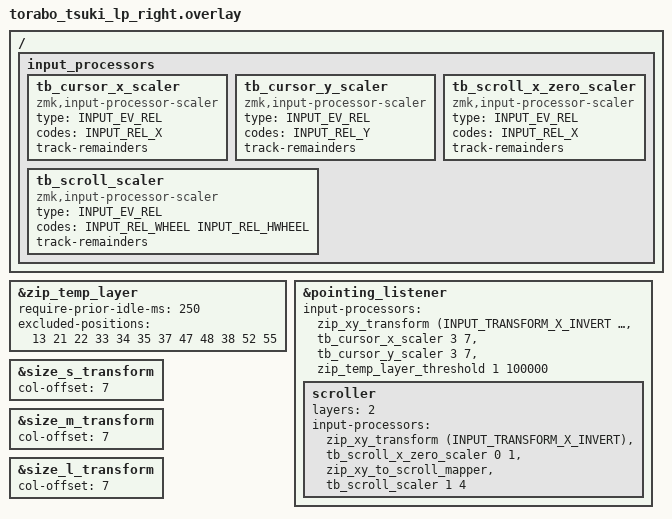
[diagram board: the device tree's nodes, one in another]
#include "torabo_tsuki_lp.dtsi"
#include <input/processors.dtsi>
#include <dt-bindings/zmk/input_transform.h>
#include <zephyr/dt-bindings/input/input-event-codes.h>

/ {
    input_processors {
        tb_cursor_x_scaler: tb_cursor_x_scaler {
            compatible = "zmk,input-processor-scaler";
            #input-processor-cells = <2>;
            type = <INPUT_EV_REL>;
            codes = <INPUT_REL_X>;
            track-remainders;
        };

        tb_cursor_y_scaler: tb_cursor_y_scaler {
            compatible = "zmk,input-processor-scaler";
            #input-processor-cells = <2>;
            type = <INPUT_EV_REL>;
            codes = <INPUT_REL_Y>;
            track-remainders;
        };

        tb_scroll_scaler: tb_scroll_scaler {
            compatible = "zmk,input-processor-scaler";
            #input-processor-cells = <2>;
            type = <INPUT_EV_REL>;
            codes = <INPUT_REL_WHEEL INPUT_REL_HWHEEL>;
            track-remainders;
        };

        tb_scroll_x_zero_scaler: tb_scroll_x_zero_scaler {
            compatible = "zmk,input-processor-scaler";
            #input-processor-cells = <2>;
            type = <INPUT_EV_REL>;
            codes = <INPUT_REL_X>;
            track-remainders;
        };
    };
};

/* Auto Mouse Layer: click後の短時間維持用 */
&zip_temp_layer {
    /* キー入力直後の誤爆防止 */
    require-prior-idle-ms = <250>;

    /*
     * 非マウスキーを押したら AML を抜ける。
     * ここに入れた位置のキーだけは AML 維持。
     *
     * ※ 数字は RC(...) ではなく keymap の key position
     * ※ コメントは layer_0 での物理位置
     */
    excluded-positions = <
        /* Mouse layer で実際に使う位置 */
        13 /* Q : mo 2 */
        21 /* O : RCLK */
        22 /* P : mo 2 */
        33 /* J : MB4 */
        34 /* K : LCLK */
        35 /* L : mo 2 */
        37 /* : : MB5 */
        47 /* M : MB3 */
        48 /* , : mo 2 */

        /* modifiers */
        38 /* Left Shift */
        52 /* Left Ctrl */
        55 /* Left Alt */
    >;
};

&pointing_listener {
    /* 通常：カーソル */
    input-processors = <
        &zip_xy_transform (INPUT_TRANSFORM_X_INVERT | INPUT_TRANSFORM_Y_INVERT)
        &tb_cursor_x_scaler 3 7
        &tb_cursor_y_scaler 3 7
    
        /*
         * 1) トラボを動かしたら Mouse layer を自動ON
         * layer_Mouse = 1
         *
         * 4) クリックするまで実質残るよう、本体側は長め
         */
        &zip_temp_layer_threshold 1 100000
    >;

    /* レイヤー2：スクロール */
    scroller {
        layers = <2>;
        input-processors = <
            /* 縦だけ逆だった対策：Y反転を付けない */
            &zip_xy_transform (INPUT_TRANSFORM_X_INVERT)

            /* 横方向の移動をスクロール変換前に無効化 */
            &tb_scroll_x_zero_scaler 0 1

            /* Y方向だけスクロール化 */
            &zip_xy_to_scroll_mapper
            &tb_scroll_scaler 1 4
        >;
    };
};

&size_s_transform { col-offset = <7>; };
&size_m_transform { col-offset = <7>; };
&size_l_transform { col-offset = <7>; };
